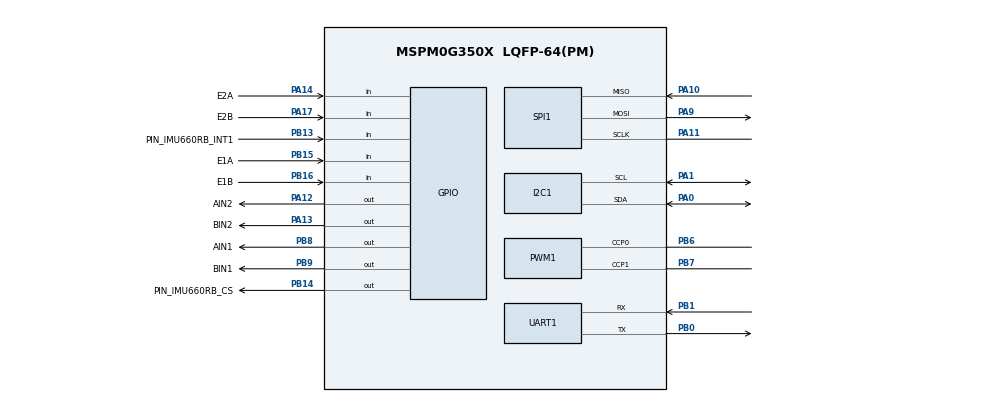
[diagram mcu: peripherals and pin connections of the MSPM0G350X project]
/**
 * @cliArgs --device "MSPM0G350X" --part "Default" --package "LQFP-64(PM)" --product "mspm0_sdk@2.05.01.01"
 * @versions {"tool":"1.24.0+4150"}
 */

/**
 * Import the modules used in this configuration.
 */
const GPIO   = scripting.addModule("/ti/driverlib/GPIO", {}, false);
const GPIO1  = GPIO.addInstance();
const GPIO2  = GPIO.addInstance();
const GPIO3  = GPIO.addInstance();
const I2C    = scripting.addModule("/ti/driverlib/I2C", {}, false);
const I2C1   = I2C.addInstance();
const PWM    = scripting.addModule("/ti/driverlib/PWM", {}, false);
const PWM1   = PWM.addInstance();
const SPI    = scripting.addModule("/ti/driverlib/SPI", {}, false);
const SPI1   = SPI.addInstance();
const SYSCTL = scripting.addModule("/ti/driverlib/SYSCTL");
const TIMER  = scripting.addModule("/ti/driverlib/TIMER", {}, false);
const TIMER1 = TIMER.addInstance();
const UART   = scripting.addModule("/ti/driverlib/UART", {}, false);
const UART1  = UART.addInstance();

/**
 * Write custom configuration values to the imported modules.
 */
const divider7       = system.clockTree["PLL_PDIV"];
divider7.divideValue = 2;

const divider9       = system.clockTree["UDIV"];
divider9.divideValue = 2;

const multiplier2         = system.clockTree["PLL_QDIV"];
multiplier2.multiplyValue = 5;

const mux8       = system.clockTree["HSCLKMUX"];
mux8.inputSelect = "HSCLKMUX_SYSPLL2X";

GPIO1.$name                         = "GPIO_Motor";
GPIO1.associatedPins.create(4);
GPIO1.associatedPins[0].$name       = "AIN1";
GPIO1.associatedPins[0].pin.$assign = "PB8";
GPIO1.associatedPins[1].$name       = "AIN2";
GPIO1.associatedPins[1].pin.$assign = "PA12";
GPIO1.associatedPins[2].$name       = "BIN1";
GPIO1.associatedPins[2].pin.$assign = "PB9";
GPIO1.associatedPins[3].$name       = "BIN2";
GPIO1.associatedPins[3].pin.$assign = "PA13";

const Board = scripting.addModule("/ti/driverlib/Board", {}, false);

GPIO2.$name                               = "GPIO_Encoder";
GPIO2.associatedPins.create(4);
GPIO2.associatedPins[0].$name             = "E1A";
GPIO2.associatedPins[0].direction         = "INPUT";
GPIO2.associatedPins[0].interruptEn       = true;
GPIO2.associatedPins[0].polarity          = "RISE";
GPIO2.associatedPins[0].interruptPriority = "0";
GPIO2.associatedPins[0].pin.$assign       = "PB15";
GPIO2.associatedPins[1].$name             = "E1B";
GPIO2.associatedPins[1].direction         = "INPUT";
GPIO2.associatedPins[1].interruptPriority = "0";
GPIO2.associatedPins[1].polarity          = "RISE";
GPIO2.associatedPins[1].pin.$assign       = "PB16";
GPIO2.associatedPins[2].$name             = "E2A";
GPIO2.associatedPins[2].direction         = "INPUT";
GPIO2.associatedPins[2].interruptEn       = true;
GPIO2.associatedPins[2].interruptPriority = "0";
GPIO2.associatedPins[2].polarity          = "RISE";
GPIO2.associatedPins[2].pin.$assign       = "PA14";
GPIO2.associatedPins[3].$name             = "E2B";
GPIO2.associatedPins[3].direction         = "INPUT";
GPIO2.associatedPins[3].interruptPriority = "0";
GPIO2.associatedPins[3].polarity          = "RISE";
GPIO2.associatedPins[3].pin.$assign       = "PA17";

GPIO3.$name                               = "GPIO_IMU660RB";
GPIO3.associatedPins.create(2);
GPIO3.associatedPins[0].$name             = "PIN_IMU660RB_INT1";
GPIO3.associatedPins[0].direction         = "INPUT";
GPIO3.associatedPins[0].interruptEn       = true;
GPIO3.associatedPins[0].interruptPriority = "3";
GPIO3.associatedPins[0].polarity          = "RISE";
GPIO3.associatedPins[0].pin.$assign       = "PB13";
GPIO3.associatedPins[1].$name             = "PIN_IMU660RB_CS";
GPIO3.associatedPins[1].pin.$assign       = "PB14";

I2C1.$name                             = "I2C_OLED";
I2C1.basicEnableController             = true;
I2C1.basicControllerStandardBusSpeed   = "Fast";
I2C1.peripheral.$assign                = "I2C0";
I2C1.peripheral.sdaPin.$assign         = "PA0";
I2C1.peripheral.sclPin.$assign         = "PA1";
I2C1.sdaPinConfig.hideOutputInversion  = scripting.forceWrite(false);
I2C1.sdaPinConfig.onlyInternalResistor = scripting.forceWrite(false);
I2C1.sdaPinConfig.passedPeripheralType = scripting.forceWrite("Digital");
I2C1.sdaPinConfig.$name                = "ti_driverlib_gpio_GPIOPinGeneric3";
I2C1.sclPinConfig.hideOutputInversion  = scripting.forceWrite(false);
I2C1.sclPinConfig.onlyInternalResistor = scripting.forceWrite(false);
I2C1.sclPinConfig.passedPeripheralType = scripting.forceWrite("Digital");
I2C1.sclPinConfig.$name                = "ti_driverlib_gpio_GPIOPinGeneric4";

PWM1.$name                              = "PWM_Motor";
PWM1.timerStartTimer                    = true;
PWM1.peripheral.$assign                 = "TIMG6";
PWM1.peripheral.ccp0Pin.$assign         = "PB6";
PWM1.peripheral.ccp1Pin.$assign         = "PB7";
PWM1.PWM_CHANNEL_0.$name                = "ti_driverlib_pwm_PWMTimerCC0";
PWM1.PWM_CHANNEL_0.invert               = true;
PWM1.PWM_CHANNEL_1.$name                = "ti_driverlib_pwm_PWMTimerCC1";
PWM1.PWM_CHANNEL_1.invert               = true;
PWM1.ccp0PinConfig.direction            = scripting.forceWrite("OUTPUT");
PWM1.ccp0PinConfig.hideOutputInversion  = scripting.forceWrite(false);
PWM1.ccp0PinConfig.onlyInternalResistor = scripting.forceWrite(false);
PWM1.ccp0PinConfig.passedPeripheralType = scripting.forceWrite("Digital");
PWM1.ccp0PinConfig.$name                = "ti_driverlib_gpio_GPIOPinGeneric0";
PWM1.ccp1PinConfig.direction            = scripting.forceWrite("OUTPUT");
PWM1.ccp1PinConfig.hideOutputInversion  = scripting.forceWrite(false);
PWM1.ccp1PinConfig.onlyInternalResistor = scripting.forceWrite(false);
PWM1.ccp1PinConfig.passedPeripheralType = scripting.forceWrite("Digital");
PWM1.ccp1PinConfig.$name                = "ti_driverlib_gpio_GPIOPinGeneric1";

SPI1.$name                              = "SPI_IMU660RB";
SPI1.frameFormat                        = "MOTO3";
SPI1.sclkPinConfig.direction            = scripting.forceWrite("OUTPUT");
SPI1.sclkPinConfig.onlyInternalResistor = scripting.forceWrite(false);
SPI1.sclkPinConfig.passedPeripheralType = scripting.forceWrite("Digital");
SPI1.sclkPinConfig.$name                = "ti_driverlib_gpio_GPIOPinGeneric2";
SPI1.mosiPinConfig.$name                = "ti_driverlib_gpio_GPIOPinGeneric5";
SPI1.mosiPinConfig.direction            = scripting.forceWrite("OUTPUT");
SPI1.mosiPinConfig.hideOutputInversion  = scripting.forceWrite(false);
SPI1.mosiPinConfig.onlyInternalResistor = scripting.forceWrite(false);
SPI1.mosiPinConfig.passedPeripheralType = scripting.forceWrite("Digital");
SPI1.misoPinConfig.$name                = "ti_driverlib_gpio_GPIOPinGeneric6";
SPI1.misoPinConfig.onlyInternalResistor = scripting.forceWrite(false);
SPI1.misoPinConfig.passedPeripheralType = scripting.forceWrite("Digital");
SPI1.peripheral.$assign                 = "SPI0";
SPI1.peripheral.sclkPin.$assign         = "PA11";
SPI1.peripheral.mosiPin.$assign         = "PA9";
SPI1.peripheral.misoPin.$assign         = "PA10";

SYSCTL.forceDefaultClkConfig = true;
SYSCTL.clockTreeEn           = true;
scripting.suppress("For best practices when the CPUCLK is running at 32MHz and above, clear the flash status bit using DL_FlashCTL_executeClearStatus\\(\\) before executing any flash operation\\. Otherwise there may be false positives\\.", SYSCTL);

TIMER1.$name              = "PIT_FOR_CONTROL";
TIMER1.timerClkDiv        = 8;
TIMER1.timerClkPrescale   = 40;
TIMER1.timerPeriod        = "20 ms";
TIMER1.timerMode          = "PERIODIC_UP";
TIMER1.timerStartTimer    = true;
TIMER1.interrupts         = ["LOAD"];
TIMER1.interruptPriority  = "2";
TIMER1.peripheral.$assign = "TIMG0";

UART1.$name                    = "UART_0";
UART1.interruptPriority        = "2";
UART1.peripheral.$assign       = "UART0";
UART1.peripheral.rxPin.$assign = "PB1";
UART1.peripheral.txPin.$assign = "PB0";
UART1.txPinConfig.$name        = "ti_driverlib_gpio_GPIOPinGeneric7";
UART1.rxPinConfig.$name        = "ti_driverlib_gpio_GPIOPinGeneric8";

/**
 * Pinmux solution for unlocked pins/peripherals. This ensures that minor changes to the automatic solver in a future
 * version of the tool will not impact the pinmux you originally saw.  These lines can be completely deleted in order to
 * re-solve from scratch.
 */
Board.peripheral.$suggestSolution          = "DEBUGSS";
Board.peripheral.swclkPin.$suggestSolution = "PA20";
Board.peripheral.swdioPin.$suggestSolution = "PA19";
